# RE01_256KB register map
Vendor: Renesas Electronics Corporation; Series: RE01; File version: 1.00.01
CPU: CM0PLUS r0p1, little endian, MPU, no FPU, VTOR, 2 interrupt priority bits, 32 interrupts
Registers are 8-bit, read-write, reset 0x0 unless marked. A register's access mark holds for its fields unless they carry their own. Offsets are from the block's base; [hi:lo] are bit positions; {n}, {i} and the like mark numbered series.

## ICU — Interrupt Controller
Base 0x40006000
{0x0+i} IRQCR{i} (i=0..9) — IRQ Control Register
  [1:0] IRQMD — IRQi Detection Sense Select
    0=Falling edge; 1=Rising edge; 2=Rising and falling edges; 3=Low level
0x100 NMICR — NMI Pin Interrupt Control Register
  [0] NMIMD — NMI Detection Set
    0=Falling edge; 1=Rising edge
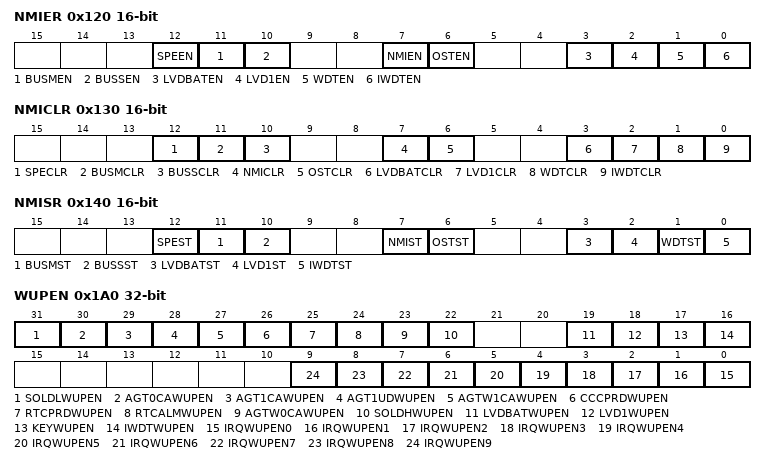
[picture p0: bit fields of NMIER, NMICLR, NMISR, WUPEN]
0x120 NMIER 16-bit — Non-Maskable Interrupt Enable Register
  [all] fields
    0=Disabled; 1=Enabled
  [12] SPEEN — CPU Stack Pointer Monitor Interrupt Enable
  [11] BUSMEN — MPU Bus Master Error Interrupt Enable
  [10] BUSSEN — MPU Bus Slave Error Interrupt Enable
  [7] NMIEN — NMI Pin Interrupt Enable
  [6] OSTEN — Oscillation Stop Detection Interrupt Enable
  [3] LVDBATEN — Voltage monitor BAT Interrupt Enable
  [2] LVD1EN — Voltage monitor 1 Interrupt Enable
  [1] WDTEN — WDT Underflow/Refresh Error Interrupt Enable
  [0] IWDTEN — IWDT Underflow/Refresh Error Interrupt Enable
0x130 NMICLR 16-bit — Non-Maskable Interrupt Status Clear Register
  [12] SPECLR — CPU Stack Pointer Monitor Interrupt Clear
    0=No effect; 1=Clear the NMISR.SPEST flag
  [11] BUSMCLR — Bus Master Error Clear
    0=No effect; 1=Clear the NMISR.BUSMST flag
  [10] BUSSCLR — Bus Slave Error Clear
    0=No effect; 1=Clear the NMISR.BUSSST flag
  [7] NMICLR — NMI Clear
    0=No effect; 1=Clear the NMISR.NMIST flag
  [6] OSTCLR — OST Clear
    0=No effect; 1=Clear the NMISR.OSTST flag
  [3] LVDBATCLR — LVDBAT Clear
    0=No effect; 1=Clear the NMISR.LVDBATST flag
  [2] LVD1CLR — LVD1 Clear
    0=No effect; 1=Clear the NMISR.LVD1ST flag
  [1] WDTCLR — WDT Clear
    0=No effect; 1=Clear the NMISR.WDTST flag
  [0] IWDTCLR — IWDT Clear
    0=No effect; 1=Clear the NMISR.IWDTST flag
0x140 NMISR 16-bit ro — Non-Maskable Interrupt Status Register
  [12] SPEST — CPU Stack Pointer Monitor Interrupt Status Flag
    0=Interrupt not requested; 1=Interrupt requested
  [11] BUSMST — MPU Bus Master Error Interrupt Status Flag
    0=Interrupt not requested; 1=Interrupt requested
  [10] BUSSST — MPU Bus Slave Error Interrupt Status Flag
    0=Interrupt not requested; 1=Interrupt requested
  [7] NMIST — NMI Status Flag
    0=Interrupt not requested; 1=Interrupt requested
  [6] OSTST — Oscillation Stop Detection Interrupt Status Flag
    0=Interrupt not requested for main oscillation stop; 1=Interrupt requested for main oscillation stop
  [3] LVDBATST — Voltage Monitor BAT Interrupt Status Flag
    0=Interrupt not requested; 1=Interrupt requested
  [2] LVD1ST — Voltage Monitor 1 Interrupt Status Flag
    0=Interrupt not requested; 1=Interrupt requested
  [1] WDTST — WDT Underflow/Refresh Error Status Flag
    0=Interrupt not requested; 1=Interrupt requested
  [0] IWDTST — IWDT Underflow/Refresh Error Status Flag
    0=Interrupt not requested; 1=Interrupt requested
0x1A0 WUPEN 32-bit — Wake Up Interrupt Enable Register
  [31] SOLDLWUPEN — SOL_DL Interrupt Software Standby Returns Enable
    0=Disable Software Standby returns by SOL_DL (falling of CMPOUT) interrupts; 1=Enable Software Standby returns by SOL_DL (falling of CMPOUT) interrupts
  [30] AGT0CAWUPEN — AGT0_AGTCMAI Interrupt Software Standby Returns Enable
    0=Disable Software Standby returns by AGT0_AGTCMAI interrupts; 1=Enable Software Standby returns by AGT0_AGTCMAI interrupts
  [29] AGT1CAWUPEN — AGT1_AGTCMAI Interrupt Software Standby Returns Enable
    0=Disable Software Standby returns by AGT1_AGTCMAI interrupts; 1=Enable Software Standby returns by AGT1_AGTCMAI interrupts
  [28] AGT1UDWUPEN — AGT1_AGTI Interrupt Software Standby Returns Enable
    0=Disable Software Standby returns by AGT1_AGTI interrupts; 1=Enable Software Standby returns by AGT1_AGTI interrupts
  [27] AGTW1CAWUPEN — AGTW1_AGTCMAI Interrupt Software Standby Returns Enable
    0=Disable Software Standby returns by AGTW1_AGTCMAI interrupts; 1=Enable Software Standby returns by AGTW1_AGTCMAI interrupts
  [26] CCCPRDWUPEN — CCC_PRD Interrupt Software Standby Returns Enable
    0=Disable Software Standby returns by CCC_PRD period interrupts; 1=Enable Software Standby returns by CCC_PRD period interrupts
  [25] RTCPRDWUPEN — RTC_PRD Interrupt Software Standby Returns Enable
    0=Disable Software Standby returns by RTC_PRD period interrupts; 1=Enable Software Standby returns by RTC_PRD period interrupts
  [24] RTCALMWUPEN — RTC_ALM Interrupt Software Standby Returns Enable
    0=Disable Software Standby returns by RTC_ALM alarm interrupts; 1=Enable Software Standby returns by RTC_ALM alarm interrupts
  [23] AGTW0CAWUPEN — AGTW0_AGTCMAI Interrupt Software Standby Returns Enable
    0=Disable Software Standby returns by AGTW0_AGTCMAI interrupts; 1=Enable Software Standby returns by AGTW0_AGTCMAI interrupts
  [22] SOLDHWUPEN — SOL_DH Interrupt Software Standby Returns Enable
    0=Disable Software Standby returns by SOL_DH (rising of CMPOUT) interrupts; 1=Enable Software Standby returns by SOL_DH (rising of CMPOUT) interrupts
  [19] LVDBATWUPEN — LVD_LVDBAT Interrupt Software Standby Returns Enable
    0=Disable Software Standby returns by LVD_LVDBAT interrupts; 1=Enable Software Standby returns by LVD_LVDBAT interrupts
  [18] LVD1WUPEN — LVD_LVD1 Interrupt Software Standby Returns Enable
    0=Disable Software Standby returns by LVD_LVD1 interrupts; 1=Enable Software Standby returns by LVD_LVD1 interrupts
  [17] KEYWUPEN — KEY_INTKR Interrupt Software Standby Returns Enable
    0=Disable Software Standby returns by KEY_INTKR interrupts; 1=Enable Software Standby returns by KEY_INTKR interrupts
  [16] IWDTWUPEN — IWDT_NMIUNDF Interrupt Software Standby Returns Enable
    0=Disable Software Standby returns by IWDT_NMIUNDF interrupts; 1=Enable Software Standby returns by IWDT_NMIUNDF interrupts
  [n] IRQWUPEN{n} (n=0..9) — PORT_IRQ{n} Interrupt Software Standby Returns Enable
    0=Disable Software Standby returns by IRQ{n} interrupts; 1=Enable Software Standby returns by IRQ{n} interrupts
0x200 SELSR0 16-bit — SYS Event Link Setting Register
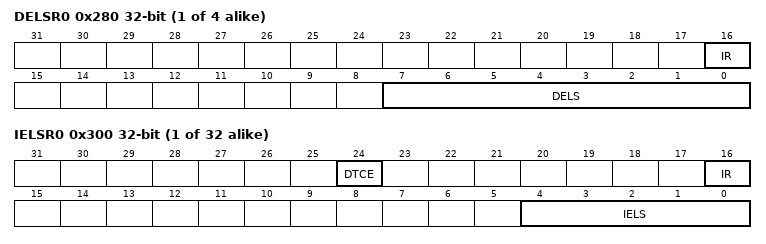
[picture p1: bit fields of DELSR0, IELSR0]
{0x280+4i} DELSR{i} (i=0..3) 32-bit — DMAC Event Link Setting Register {i}
  [16] IR — DMAC Activation Request Status flag
    0=No DMAC activation request occurred; 1=DMAC activation request occurred
  [7:0] DELS — DMAC Event Link Select
    0=Disable interrupts to the associated DMAC module; other=Others (Event signal number to be linked. For details, see Table x.x Event table.)
{0x300+4i} IELSR{i} (i=0..31) 32-bit — ICU Event Link Setting Register {i}
  [24] DTCE — DTC Activation Enable
    0=DTC activation is disabled; 1=DTC activation is enabled
  [16] IR — Interrupt Status Flag
    0=No interrupt request generated; 1=An interrupt request is generated
  [4:0] IELS — ICU Event Link Select
    0=Disable interrupts to the associated NVIC or DTC module; other=Others (Event signal number to be linked.)
